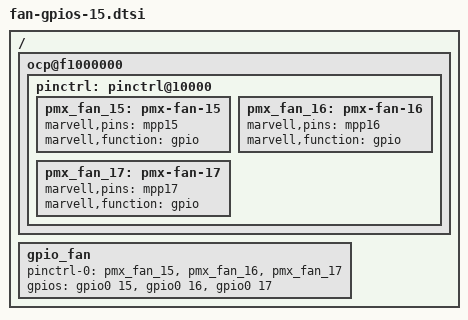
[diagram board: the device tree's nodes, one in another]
/*
 * Andrew Lunn <andrew@lunn.ch>
 *
 * This file is licensed under the terms of the GNU General Public
 * License version 2.  This program is licensed "as is" without any
 * warranty of any kind, whether express or implied.
 */

/ {
	ocp@f1000000 {
		pinctrl: pinctrl@10000 {

			pmx_fan_15: pmx-fan-15 {
				marvell,pins = "mpp15";
				marvell,function = "gpio";
			};
			pmx_fan_16: pmx-fan-16 {
				marvell,pins = "mpp16";
				marvell,function = "gpio";
			};
			pmx_fan_17: pmx-fan-17 {
				marvell,pins = "mpp17";
				marvell,function = "gpio";
			};
		};
	};
	gpio_fan {
		pinctrl-0 = <&pmx_fan_15 &pmx_fan_16 &pmx_fan_17>;
		pinctrl-names = "default";
		gpios = <&gpio0 15 GPIO_ACTIVE_HIGH
			 &gpio0 16 GPIO_ACTIVE_HIGH
			 &gpio0 17 GPIO_ACTIVE_HIGH>;
	};
};
